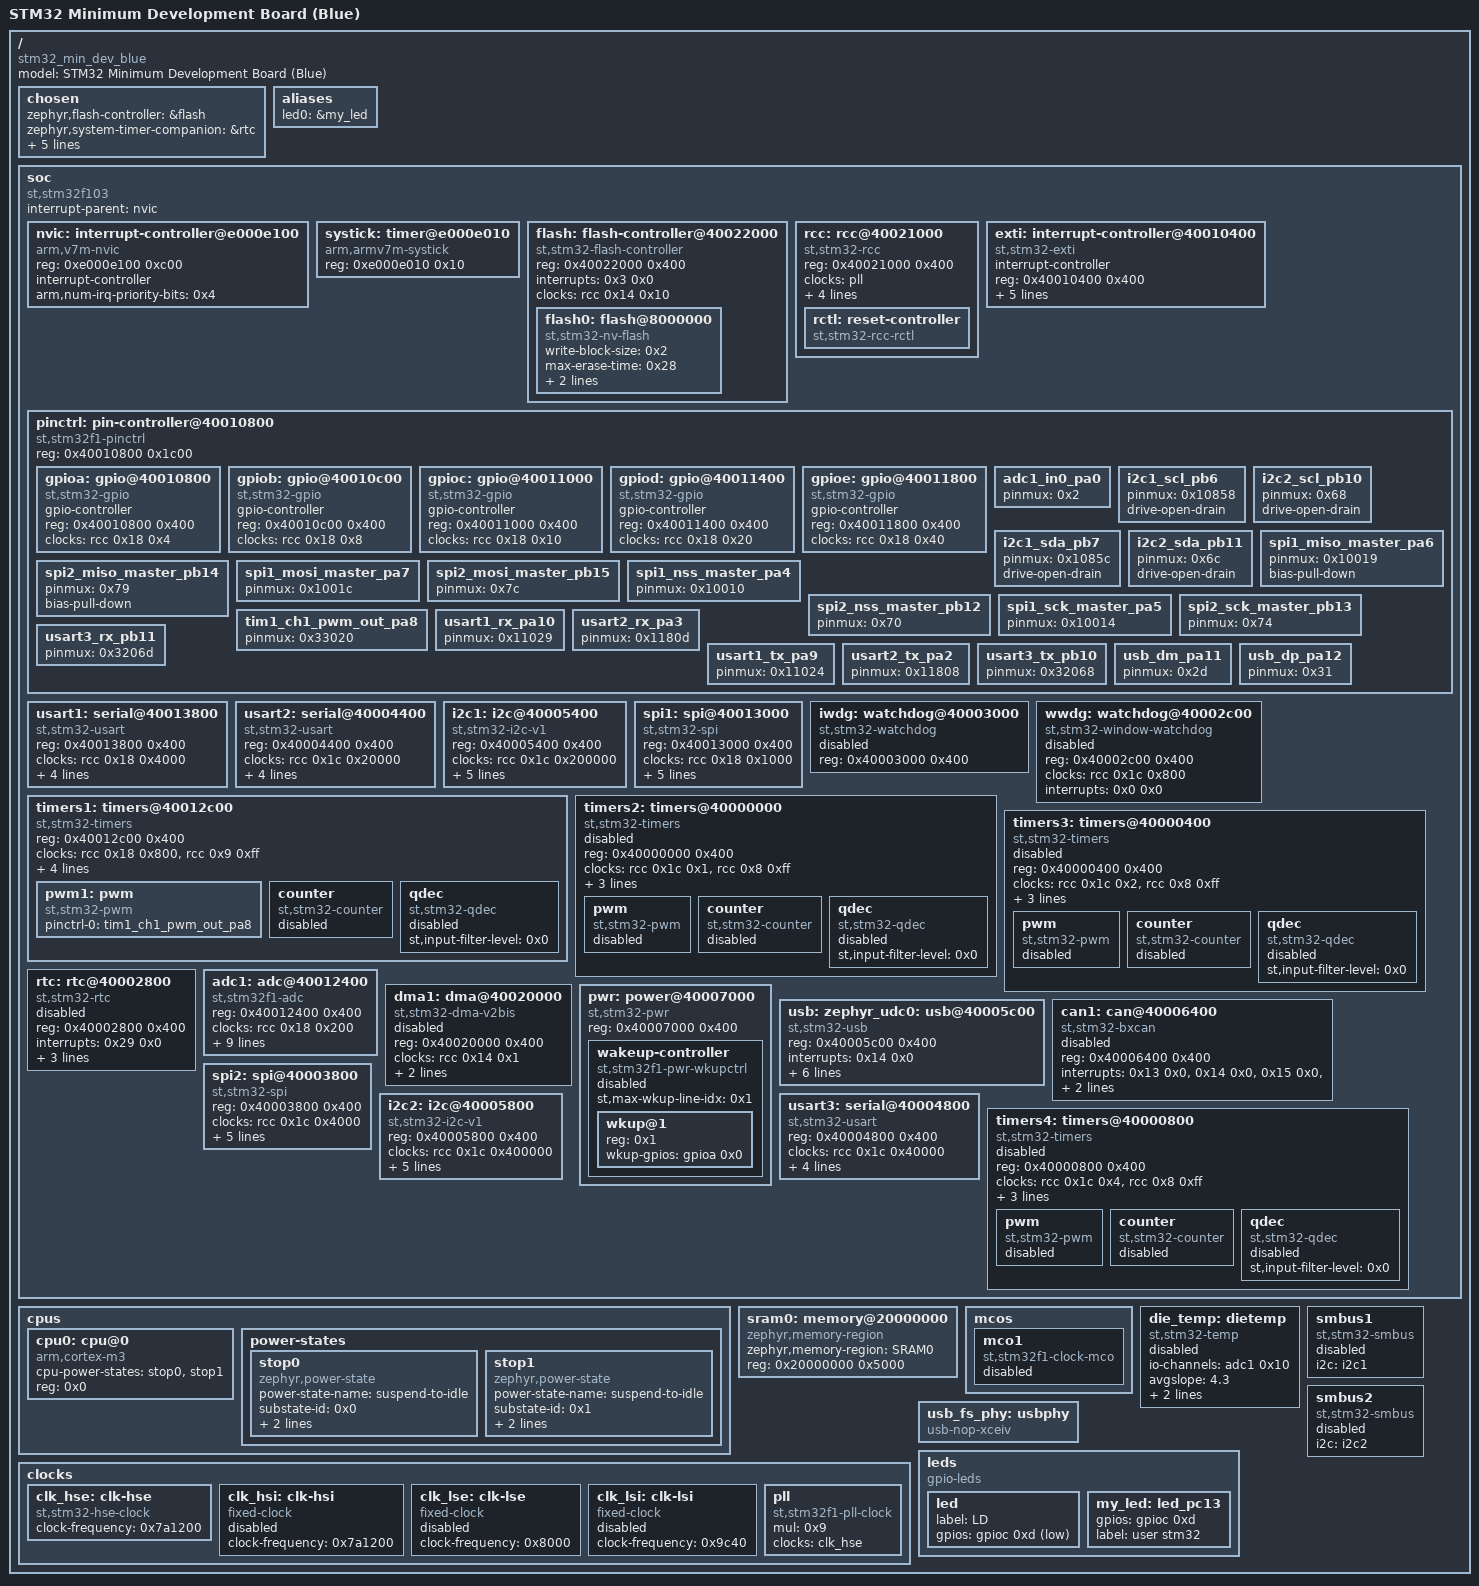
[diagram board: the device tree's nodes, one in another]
/dts-v1/;

/* node '/' defined in zephyr/dts/common/skeleton.dtsi:9 */
/ {
	#address-cells = < 0x1 >;                         /* in zephyr/dts/common/skeleton.dtsi:10 */
	#size-cells = < 0x1 >;                            /* in zephyr/dts/common/skeleton.dtsi:11 */
	model = "STM32 Minimum Development Board (Blue)"; /* in zephyr/boards/others/stm32_min_dev/stm32_min_dev_stm32f103x8_blue.overlay:8 */
	compatible = "stm32_min_dev_blue",
	             "st,stm32f103c8";                    /* in zephyr/boards/others/stm32_min_dev/stm32_min_dev_stm32f103x8_blue.overlay:9 */

	/* node '/chosen' defined in zephyr/dts/common/skeleton.dtsi:13 */
	chosen {
		zephyr,flash-controller = &flash;     /* in zephyr/dts/arm/st/f1/stm32f1.dtsi:24 */
		zephyr,system-timer-companion = &rtc; /* in zephyr/dts/arm/st/f1/stm32f1.dtsi:25 */
		zephyr,console = &usart1;             /* in zephyr/boards/others/stm32_min_dev/stm32_min_dev.dts:16 */
		zephyr,shell-uart = &usart1;          /* in zephyr/boards/others/stm32_min_dev/stm32_min_dev.dts:17 */
		zephyr,osdp-uart = &usart2;           /* in zephyr/boards/others/stm32_min_dev/stm32_min_dev.dts:18 */
		zephyr,sram = &sram0;                 /* in zephyr/boards/others/stm32_min_dev/stm32_min_dev.dts:19 */
		zephyr,flash = &flash0;               /* in zephyr/boards/others/stm32_min_dev/stm32_min_dev.dts:20 */
	};

	/* node '/aliases' defined in zephyr/dts/common/skeleton.dtsi:15 */
	aliases {
		led0 = &my_led; /* in ../Zephyr_Prj/Blink_led/boards/stm32_min_dev_blue.overlay:3 */
	};

	/* node '/soc' defined in zephyr/dts/arm/armv7-m.dtsi:6 */
	soc {
		#address-cells = < 0x1 >;     /* in zephyr/dts/arm/armv7-m.dtsi:7 */
		#size-cells = < 0x1 >;        /* in zephyr/dts/arm/armv7-m.dtsi:8 */
		interrupt-parent = < &nvic >; /* in zephyr/dts/arm/armv7-m.dtsi:10 */
		ranges;                       /* in zephyr/dts/arm/armv7-m.dtsi:11 */
		compatible = "st,stm32f103",
		             "st,stm32f1",
		             "simple-bus";    /* in zephyr/dts/arm/st/f1/stm32f103X6.dtsi:14 */

		/* node '/soc/interrupt-controller@e000e100' defined in zephyr/dts/arm/armv7-m.dtsi:13 */
		nvic: interrupt-controller@e000e100 {
			#address-cells = < 0x1 >;            /* in zephyr/dts/arm/armv7-m.dtsi:14 */
			compatible = "arm,v7m-nvic";         /* in zephyr/dts/arm/armv7-m.dtsi:15 */
			reg = < 0xe000e100 0xc00 >;          /* in zephyr/dts/arm/armv7-m.dtsi:16 */
			interrupt-controller;                /* in zephyr/dts/arm/armv7-m.dtsi:17 */
			#interrupt-cells = < 0x2 >;          /* in zephyr/dts/arm/armv7-m.dtsi:18 */
			arm,num-irq-priority-bits = < 0x4 >; /* in zephyr/dts/arm/st/f1/stm32f1.dtsi:417 */
			phandle = < 0x1 >;                   /* in zephyr/dts/arm/armv7-m.dtsi:10 */
		};

		/* node '/soc/timer@e000e010' defined in zephyr/dts/arm/armv7-m.dtsi:21 */
		systick: timer@e000e010 {
			compatible = "arm,armv7m-systick"; /* in zephyr/dts/arm/armv7-m.dtsi:22 */
			reg = < 0xe000e010 0x10 >;         /* in zephyr/dts/arm/armv7-m.dtsi:23 */
		};

		/* node '/soc/flash-controller@40022000' defined in zephyr/dts/arm/st/f1/stm32f1.dtsi:107 */
		flash: flash-controller@40022000 {
			compatible = "st,stm32-flash-controller",
			             "st,stm32f1-flash-controller"; /* in zephyr/dts/arm/st/f1/stm32f1.dtsi:108 */
			reg = < 0x40022000 0x400 >;                 /* in zephyr/dts/arm/st/f1/stm32f1.dtsi:109 */
			interrupts = < 0x3 0x0 >;                   /* in zephyr/dts/arm/st/f1/stm32f1.dtsi:110 */
			clocks = < &rcc 0x14 0x10 >;                /* in zephyr/dts/arm/st/f1/stm32f1.dtsi:111 */
			#address-cells = < 0x1 >;                   /* in zephyr/dts/arm/st/f1/stm32f1.dtsi:113 */
			#size-cells = < 0x1 >;                      /* in zephyr/dts/arm/st/f1/stm32f1.dtsi:114 */
			ranges;                                     /* in zephyr/dts/arm/st/f1/stm32f1.dtsi:115 */

			/* node '/soc/flash-controller@40022000/flash@8000000' defined in zephyr/dts/arm/st/f1/stm32f1.dtsi:117 */
			flash0: flash@8000000 {
				compatible = "st,stm32-nv-flash",
				             "soc-nv-flash";        /* in zephyr/dts/arm/st/f1/stm32f1.dtsi:118 */
				#address-cells = < 0x1 >;           /* in zephyr/dts/arm/st/f1/stm32f1.dtsi:119 */
				#size-cells = < 0x1 >;              /* in zephyr/dts/arm/st/f1/stm32f1.dtsi:120 */
				write-block-size = < 0x2 >;         /* in zephyr/dts/arm/st/f1/stm32f1.dtsi:121 */
				max-erase-time = < 0x28 >;          /* in zephyr/dts/arm/st/f1/stm32f1.dtsi:123 */
				reg = < 0x8000000 0x10000 >;        /* in zephyr/dts/arm/st/f1/stm32f103X8.dtsi:17 */
				ranges = < 0x0 0x8000000 0x10000 >; /* in zephyr/dts/arm/st/f1/stm32f103X8.dtsi:18 */
				erase-block-size = < 0x400 >;       /* in zephyr/dts/arm/st/f1/stm32f103X8.dtsi:19 */
			};
		};

		/* node '/soc/rcc@40021000' defined in zephyr/dts/arm/st/f1/stm32f1.dtsi:127 */
		rcc: rcc@40021000 {
			compatible = "st,stm32-rcc";     /* in zephyr/dts/arm/st/f1/stm32f1.dtsi:128 */
			#clock-cells = < 0x2 >;          /* in zephyr/dts/arm/st/f1/stm32f1.dtsi:129 */
			reg = < 0x40021000 0x400 >;      /* in zephyr/dts/arm/st/f1/stm32f1.dtsi:130 */
			clocks = < &pll >;               /* in zephyr/boards/others/stm32_min_dev/stm32_min_dev.dts:49 */
			clock-frequency = < 0x44aa200 >; /* in zephyr/boards/others/stm32_min_dev/stm32_min_dev.dts:50 */
			ahb-prescaler = < 0x1 >;         /* in zephyr/boards/others/stm32_min_dev/stm32_min_dev.dts:51 */
			apb1-prescaler = < 0x2 >;        /* in zephyr/boards/others/stm32_min_dev/stm32_min_dev.dts:52 */
			apb2-prescaler = < 0x1 >;        /* in zephyr/boards/others/stm32_min_dev/stm32_min_dev.dts:53 */
			phandle = < 0x2 >;               /* in zephyr/dts/arm/st/f1/stm32f1.dtsi:111 */

			/* node '/soc/rcc@40021000/reset-controller' defined in zephyr/dts/arm/st/f1/stm32f1.dtsi:132 */
			rctl: reset-controller {
				compatible = "st,stm32-rcc-rctl"; /* in zephyr/dts/arm/st/f1/stm32f1.dtsi:133 */
				#reset-cells = < 0x1 >;           /* in zephyr/dts/arm/st/f1/stm32f1.dtsi:134 */
				phandle = < 0x4 >;                /* in zephyr/dts/arm/st/f1/stm32f1.dtsi:205 */
			};
		};

		/* node '/soc/interrupt-controller@40010400' defined in zephyr/dts/arm/st/f1/stm32f1.dtsi:138 */
		exti: interrupt-controller@40010400 {
			compatible = "st,stm32-exti";  /* in zephyr/dts/arm/st/f1/stm32f1.dtsi:139 */
			interrupt-controller;          /* in zephyr/dts/arm/st/f1/stm32f1.dtsi:140 */
			#interrupt-cells = < 0x1 >;    /* in zephyr/dts/arm/st/f1/stm32f1.dtsi:141 */
			#address-cells = < 0x0 >;      /* in zephyr/dts/arm/st/f1/stm32f1.dtsi:142 */
			reg = < 0x40010400 0x400 >;    /* in zephyr/dts/arm/st/f1/stm32f1.dtsi:143 */
			num-lines = < 0x20 >;          /* in zephyr/dts/arm/st/f1/stm32f1.dtsi:144 */
			interrupts = < 0x6 0x0 >,
			             < 0x7 0x0 >,
			             < 0x8 0x0 >,
			             < 0x9 0x0 >,
			             < 0xa 0x0 >,
			             < 0x17 0x0 >,
			             < 0x28 0x0 >;     /* in zephyr/dts/arm/st/f1/stm32f1.dtsi:145 */
			interrupt-names = "line0",
			                  "line1",
			                  "line2",
			                  "line3",
			                  "line4",
			                  "line5-9",
			                  "line10-15"; /* in zephyr/dts/arm/st/f1/stm32f1.dtsi:147 */
			line-ranges = < 0x0 0x1 >,
			              < 0x1 0x1 >,
			              < 0x2 0x1 >,
			              < 0x3 0x1 >,
			              < 0x4 0x1 >,
			              < 0x5 0x5 >,
			              < 0xa 0x6 >;     /* in zephyr/dts/arm/st/f1/stm32f1.dtsi:149 */
		};

		/* node '/soc/pin-controller@40010800' defined in zephyr/dts/arm/st/f1/stm32f1.dtsi:153 */
		pinctrl: pin-controller@40010800 {
			compatible = "st,stm32f1-pinctrl"; /* in zephyr/dts/arm/st/f1/stm32f1.dtsi:154 */
			#address-cells = < 0x1 >;          /* in zephyr/dts/arm/st/f1/stm32f1.dtsi:155 */
			#size-cells = < 0x1 >;             /* in zephyr/dts/arm/st/f1/stm32f1.dtsi:156 */
			reg = < 0x40010800 0x1c00 >;       /* in zephyr/dts/arm/st/f1/stm32f1.dtsi:157 */
			ranges;                            /* in zephyr/dts/arm/st/f1/stm32f1.dtsi:158 */

			/* node '/soc/pin-controller@40010800/gpio@40010800' defined in zephyr/dts/arm/st/f1/stm32f1.dtsi:160 */
			gpioa: gpio@40010800 {
				compatible = "st,stm32-gpio"; /* in zephyr/dts/arm/st/f1/stm32f1.dtsi:161 */
				gpio-controller;              /* in zephyr/dts/arm/st/f1/stm32f1.dtsi:162 */
				#gpio-cells = < 0x2 >;        /* in zephyr/dts/arm/st/f1/stm32f1.dtsi:163 */
				reg = < 0x40010800 0x400 >;   /* in zephyr/dts/arm/st/f1/stm32f1.dtsi:164 */
				clocks = < &rcc 0x18 0x4 >;   /* in zephyr/dts/arm/st/f1/stm32f1.dtsi:165 */
				phandle = < 0x12 >;           /* in zephyr/dts/arm/st/f1/stm32f1.dtsi:392 */
			};

			/* node '/soc/pin-controller@40010800/gpio@40010c00' defined in zephyr/dts/arm/st/f1/stm32f1.dtsi:168 */
			gpiob: gpio@40010c00 {
				compatible = "st,stm32-gpio"; /* in zephyr/dts/arm/st/f1/stm32f1.dtsi:169 */
				gpio-controller;              /* in zephyr/dts/arm/st/f1/stm32f1.dtsi:170 */
				#gpio-cells = < 0x2 >;        /* in zephyr/dts/arm/st/f1/stm32f1.dtsi:171 */
				reg = < 0x40010c00 0x400 >;   /* in zephyr/dts/arm/st/f1/stm32f1.dtsi:172 */
				clocks = < &rcc 0x18 0x8 >;   /* in zephyr/dts/arm/st/f1/stm32f1.dtsi:173 */
				phandle = < 0xb >;            /* in zephyr/boards/others/stm32_min_dev/stm32_min_dev.dts:82 */
			};

			/* node '/soc/pin-controller@40010800/gpio@40011000' defined in zephyr/dts/arm/st/f1/stm32f1.dtsi:176 */
			gpioc: gpio@40011000 {
				compatible = "st,stm32-gpio"; /* in zephyr/dts/arm/st/f1/stm32f1.dtsi:177 */
				gpio-controller;              /* in zephyr/dts/arm/st/f1/stm32f1.dtsi:178 */
				#gpio-cells = < 0x2 >;        /* in zephyr/dts/arm/st/f1/stm32f1.dtsi:179 */
				reg = < 0x40011000 0x400 >;   /* in zephyr/dts/arm/st/f1/stm32f1.dtsi:180 */
				clocks = < &rcc 0x18 0x10 >;  /* in zephyr/dts/arm/st/f1/stm32f1.dtsi:181 */
				status = "okay";              /* in ../Zephyr_Prj/Blink_led/boards/stm32_min_dev_blue.overlay:17 */
				phandle = < 0x24 >;           /* in zephyr/boards/others/stm32_min_dev/stm32_min_dev_stm32f103x8_blue.overlay:13 */
			};

			/* node '/soc/pin-controller@40010800/gpio@40011400' defined in zephyr/dts/arm/st/f1/stm32f1.dtsi:184 */
			gpiod: gpio@40011400 {
				compatible = "st,stm32-gpio"; /* in zephyr/dts/arm/st/f1/stm32f1.dtsi:185 */
				gpio-controller;              /* in zephyr/dts/arm/st/f1/stm32f1.dtsi:186 */
				#gpio-cells = < 0x2 >;        /* in zephyr/dts/arm/st/f1/stm32f1.dtsi:187 */
				reg = < 0x40011400 0x400 >;   /* in zephyr/dts/arm/st/f1/stm32f1.dtsi:188 */
				clocks = < &rcc 0x18 0x20 >;  /* in zephyr/dts/arm/st/f1/stm32f1.dtsi:189 */
			};

			/* node '/soc/pin-controller@40010800/gpio@40011800' defined in zephyr/dts/arm/st/f1/stm32f1.dtsi:192 */
			gpioe: gpio@40011800 {
				compatible = "st,stm32-gpio"; /* in zephyr/dts/arm/st/f1/stm32f1.dtsi:193 */
				gpio-controller;              /* in zephyr/dts/arm/st/f1/stm32f1.dtsi:194 */
				#gpio-cells = < 0x2 >;        /* in zephyr/dts/arm/st/f1/stm32f1.dtsi:195 */
				reg = < 0x40011800 0x400 >;   /* in zephyr/dts/arm/st/f1/stm32f1.dtsi:196 */
				clocks = < &rcc 0x18 0x40 >;  /* in zephyr/dts/arm/st/f1/stm32f1.dtsi:197 */
			};

			/* node '/soc/pin-controller@40010800/adc1_in0_pa0' defined in modules/hal/stm32/dts/st/f1/stm32f103r(8-b)tx-pinctrl.dtsi:11 */
			adc1_in0_pa0: adc1_in0_pa0 {
				pinmux = < 0x2 >;   /* in modules/hal/stm32/dts/st/f1/stm32f103r(8-b)tx-pinctrl.dtsi:12 */
				phandle = < 0x11 >; /* in zephyr/boards/others/stm32_min_dev/stm32_min_dev.dts:127 */
			};

			/* node '/soc/pin-controller@40010800/i2c1_scl_pb6' defined in modules/hal/stm32/dts/st/f1/stm32f103r(8-b)tx-pinctrl.dtsi:363 */
			i2c1_scl_pb6: i2c1_scl_pb6 {
				pinmux = < 0x10858 >; /* in modules/hal/stm32/dts/st/f1/stm32f103r(8-b)tx-pinctrl.dtsi:364 */
				drive-open-drain;     /* in modules/hal/stm32/dts/st/f1/stm32f103r(8-b)tx-pinctrl.dtsi:365 */
				phandle = < 0x9 >;    /* in zephyr/boards/others/stm32_min_dev/stm32_min_dev.dts:79 */
			};

			/* node '/soc/pin-controller@40010800/i2c2_scl_pb10' defined in modules/hal/stm32/dts/st/f1/stm32f103r(8-b)tx-pinctrl.dtsi:373 */
			i2c2_scl_pb10: i2c2_scl_pb10 {
				pinmux = < 0x68 >;  /* in modules/hal/stm32/dts/st/f1/stm32f103r(8-b)tx-pinctrl.dtsi:374 */
				drive-open-drain;   /* in modules/hal/stm32/dts/st/f1/stm32f103r(8-b)tx-pinctrl.dtsi:375 */
				phandle = < 0x1c >; /* in zephyr/boards/others/stm32_min_dev/stm32_min_dev.dts:88 */
			};

			/* node '/soc/pin-controller@40010800/i2c1_sda_pb7' defined in modules/hal/stm32/dts/st/f1/stm32f103r(8-b)tx-pinctrl.dtsi:379 */
			i2c1_sda_pb7: i2c1_sda_pb7 {
				pinmux = < 0x1085c >; /* in modules/hal/stm32/dts/st/f1/stm32f103r(8-b)tx-pinctrl.dtsi:380 */
				drive-open-drain;     /* in modules/hal/stm32/dts/st/f1/stm32f103r(8-b)tx-pinctrl.dtsi:381 */
				phandle = < 0xa >;    /* in zephyr/boards/others/stm32_min_dev/stm32_min_dev.dts:79 */
			};

			/* node '/soc/pin-controller@40010800/i2c2_sda_pb11' defined in modules/hal/stm32/dts/st/f1/stm32f103r(8-b)tx-pinctrl.dtsi:389 */
			i2c2_sda_pb11: i2c2_sda_pb11 {
				pinmux = < 0x6c >;  /* in modules/hal/stm32/dts/st/f1/stm32f103r(8-b)tx-pinctrl.dtsi:390 */
				drive-open-drain;   /* in modules/hal/stm32/dts/st/f1/stm32f103r(8-b)tx-pinctrl.dtsi:391 */
				phandle = < 0x1d >; /* in zephyr/boards/others/stm32_min_dev/stm32_min_dev.dts:88 */
			};

			/* node '/soc/pin-controller@40010800/spi1_miso_master_pa6' defined in modules/hal/stm32/dts/st/f1/stm32f103r(8-b)tx-pinctrl.dtsi:426 */
			spi1_miso_master_pa6: spi1_miso_master_pa6 {
				pinmux = < 0x10019 >; /* in modules/hal/stm32/dts/st/f1/stm32f103r(8-b)tx-pinctrl.dtsi:427 */
				bias-pull-down;       /* in modules/hal/stm32/dts/st/f1/stm32f103r(8-b)tx-pinctrl.dtsi:428 */
				phandle = < 0xe >;    /* in zephyr/boards/others/stm32_min_dev/stm32_min_dev.dts:97 */
			};

			/* node '/soc/pin-controller@40010800/spi2_miso_master_pb14' defined in modules/hal/stm32/dts/st/f1/stm32f103r(8-b)tx-pinctrl.dtsi:436 */
			spi2_miso_master_pb14: spi2_miso_master_pb14 {
				pinmux = < 0x79 >;  /* in modules/hal/stm32/dts/st/f1/stm32f103r(8-b)tx-pinctrl.dtsi:437 */
				bias-pull-down;     /* in modules/hal/stm32/dts/st/f1/stm32f103r(8-b)tx-pinctrl.dtsi:438 */
				phandle = < 0x18 >; /* in zephyr/boards/others/stm32_min_dev/stm32_min_dev.dts:104 */
			};

			/* node '/soc/pin-controller@40010800/spi1_mosi_master_pa7' defined in modules/hal/stm32/dts/st/f1/stm32f103r(8-b)tx-pinctrl.dtsi:442 */
			spi1_mosi_master_pa7: spi1_mosi_master_pa7 {
				pinmux = < 0x1001c >; /* in modules/hal/stm32/dts/st/f1/stm32f103r(8-b)tx-pinctrl.dtsi:443 */
				phandle = < 0xf >;    /* in zephyr/boards/others/stm32_min_dev/stm32_min_dev.dts:97 */
			};

			/* node '/soc/pin-controller@40010800/spi2_mosi_master_pb15' defined in modules/hal/stm32/dts/st/f1/stm32f103r(8-b)tx-pinctrl.dtsi:450 */
			spi2_mosi_master_pb15: spi2_mosi_master_pb15 {
				pinmux = < 0x7c >;  /* in modules/hal/stm32/dts/st/f1/stm32f103r(8-b)tx-pinctrl.dtsi:451 */
				phandle = < 0x19 >; /* in zephyr/boards/others/stm32_min_dev/stm32_min_dev.dts:104 */
			};

			/* node '/soc/pin-controller@40010800/spi1_nss_master_pa4' defined in modules/hal/stm32/dts/st/f1/stm32f103r(8-b)tx-pinctrl.dtsi:455 */
			spi1_nss_master_pa4: spi1_nss_master_pa4 {
				pinmux = < 0x10010 >; /* in modules/hal/stm32/dts/st/f1/stm32f103r(8-b)tx-pinctrl.dtsi:456 */
				phandle = < 0xc >;    /* in zephyr/boards/others/stm32_min_dev/stm32_min_dev.dts:97 */
			};

			/* node '/soc/pin-controller@40010800/spi2_nss_master_pb12' defined in modules/hal/stm32/dts/st/f1/stm32f103r(8-b)tx-pinctrl.dtsi:463 */
			spi2_nss_master_pb12: spi2_nss_master_pb12 {
				pinmux = < 0x70 >;  /* in modules/hal/stm32/dts/st/f1/stm32f103r(8-b)tx-pinctrl.dtsi:464 */
				phandle = < 0x16 >; /* in zephyr/boards/others/stm32_min_dev/stm32_min_dev.dts:104 */
			};

			/* node '/soc/pin-controller@40010800/spi1_sck_master_pa5' defined in modules/hal/stm32/dts/st/f1/stm32f103r(8-b)tx-pinctrl.dtsi:468 */
			spi1_sck_master_pa5: spi1_sck_master_pa5 {
				pinmux = < 0x10014 >; /* in modules/hal/stm32/dts/st/f1/stm32f103r(8-b)tx-pinctrl.dtsi:469 */
				phandle = < 0xd >;    /* in zephyr/boards/others/stm32_min_dev/stm32_min_dev.dts:97 */
			};

			/* node '/soc/pin-controller@40010800/spi2_sck_master_pb13' defined in modules/hal/stm32/dts/st/f1/stm32f103r(8-b)tx-pinctrl.dtsi:476 */
			spi2_sck_master_pb13: spi2_sck_master_pb13 {
				pinmux = < 0x74 >;  /* in modules/hal/stm32/dts/st/f1/stm32f103r(8-b)tx-pinctrl.dtsi:477 */
				phandle = < 0x17 >; /* in zephyr/boards/others/stm32_min_dev/stm32_min_dev.dts:104 */
			};

			/* node '/soc/pin-controller@40010800/tim1_ch1_pwm_out_pa8' defined in modules/hal/stm32/dts/st/f1/stm32f103r(8-b)tx-pinctrl.dtsi:734 */
			tim1_ch1_pwm_out_pa8: tim1_ch1_pwm_out_pa8 {
				pinmux = < 0x33020 >; /* in modules/hal/stm32/dts/st/f1/stm32f103r(8-b)tx-pinctrl.dtsi:735 */
				phandle = < 0x10 >;   /* in zephyr/boards/others/stm32_min_dev/stm32_min_dev.dts:115 */
			};

			/* node '/soc/pin-controller@40010800/usart1_rx_pa10' defined in modules/hal/stm32/dts/st/f1/stm32f103r(8-b)tx-pinctrl.dtsi:957 */
			usart1_rx_pa10: usart1_rx_pa10 {
				pinmux = < 0x11029 >; /* in modules/hal/stm32/dts/st/f1/stm32f103r(8-b)tx-pinctrl.dtsi:958 */
				phandle = < 0x6 >;    /* in zephyr/boards/others/stm32_min_dev/stm32_min_dev.dts:58 */
			};

			/* node '/soc/pin-controller@40010800/usart2_rx_pa3' defined in modules/hal/stm32/dts/st/f1/stm32f103r(8-b)tx-pinctrl.dtsi:965 */
			usart2_rx_pa3: usart2_rx_pa3 {
				pinmux = < 0x1180d >; /* in modules/hal/stm32/dts/st/f1/stm32f103r(8-b)tx-pinctrl.dtsi:966 */
				phandle = < 0x8 >;    /* in zephyr/boards/others/stm32_min_dev/stm32_min_dev.dts:65 */
			};

			/* node '/soc/pin-controller@40010800/usart3_rx_pb11' defined in modules/hal/stm32/dts/st/f1/stm32f103r(8-b)tx-pinctrl.dtsi:969 */
			usart3_rx_pb11: usart3_rx_pb11 {
				pinmux = < 0x3206d >; /* in modules/hal/stm32/dts/st/f1/stm32f103r(8-b)tx-pinctrl.dtsi:970 */
				phandle = < 0x1b >;   /* in zephyr/boards/others/stm32_min_dev/stm32_min_dev.dts:72 */
			};

			/* node '/soc/pin-controller@40010800/usart1_tx_pa9' defined in modules/hal/stm32/dts/st/f1/stm32f103r(8-b)tx-pinctrl.dtsi:978 */
			usart1_tx_pa9: usart1_tx_pa9 {
				pinmux = < 0x11024 >; /* in modules/hal/stm32/dts/st/f1/stm32f103r(8-b)tx-pinctrl.dtsi:979 */
				phandle = < 0x5 >;    /* in zephyr/boards/others/stm32_min_dev/stm32_min_dev.dts:58 */
			};

			/* node '/soc/pin-controller@40010800/usart2_tx_pa2' defined in modules/hal/stm32/dts/st/f1/stm32f103r(8-b)tx-pinctrl.dtsi:986 */
			usart2_tx_pa2: usart2_tx_pa2 {
				pinmux = < 0x11808 >; /* in modules/hal/stm32/dts/st/f1/stm32f103r(8-b)tx-pinctrl.dtsi:987 */
				phandle = < 0x7 >;    /* in zephyr/boards/others/stm32_min_dev/stm32_min_dev.dts:65 */
			};

			/* node '/soc/pin-controller@40010800/usart3_tx_pb10' defined in modules/hal/stm32/dts/st/f1/stm32f103r(8-b)tx-pinctrl.dtsi:990 */
			usart3_tx_pb10: usart3_tx_pb10 {
				pinmux = < 0x32068 >; /* in modules/hal/stm32/dts/st/f1/stm32f103r(8-b)tx-pinctrl.dtsi:991 */
				phandle = < 0x1a >;   /* in zephyr/boards/others/stm32_min_dev/stm32_min_dev.dts:72 */
			};

			/* node '/soc/pin-controller@40010800/usb_dm_pa11' defined in modules/hal/stm32/dts/st/f1/stm32f103r(8-b)tx-pinctrl.dtsi:999 */
			usb_dm_pa11: usb_dm_pa11 {
				pinmux = < 0x2d >;  /* in modules/hal/stm32/dts/st/f1/stm32f103r(8-b)tx-pinctrl.dtsi:1000 */
				phandle = < 0x14 >; /* in zephyr/boards/others/stm32_min_dev/stm32_min_dev.dts:121 */
			};

			/* node '/soc/pin-controller@40010800/usb_dp_pa12' defined in modules/hal/stm32/dts/st/f1/stm32f103r(8-b)tx-pinctrl.dtsi:1003 */
			usb_dp_pa12: usb_dp_pa12 {
				pinmux = < 0x31 >;  /* in modules/hal/stm32/dts/st/f1/stm32f103r(8-b)tx-pinctrl.dtsi:1004 */
				phandle = < 0x15 >; /* in zephyr/boards/others/stm32_min_dev/stm32_min_dev.dts:121 */
			};
		};

		/* node '/soc/serial@40013800' defined in zephyr/dts/arm/st/f1/stm32f1.dtsi:201 */
		usart1: serial@40013800 {
			compatible = "st,stm32-usart",
			             "st,stm32-uart";                   /* in zephyr/dts/arm/st/f1/stm32f1.dtsi:202 */
			reg = < 0x40013800 0x400 >;                     /* in zephyr/dts/arm/st/f1/stm32f1.dtsi:203 */
			clocks = < &rcc 0x18 0x4000 >;                  /* in zephyr/dts/arm/st/f1/stm32f1.dtsi:204 */
			resets = < &rctl 0x18e >;                       /* in zephyr/dts/arm/st/f1/stm32f1.dtsi:205 */
			interrupts = < 0x25 0x0 >;                      /* in zephyr/dts/arm/st/f1/stm32f1.dtsi:206 */
			pinctrl-0 = < &usart1_tx_pa9 &usart1_rx_pa10 >; /* in zephyr/boards/others/stm32_min_dev/stm32_min_dev.dts:58 */
			current-speed = < 0x1c200 >;                    /* in zephyr/boards/others/stm32_min_dev/stm32_min_dev.dts:59 */
			pinctrl-names = "default";                      /* in zephyr/boards/others/stm32_min_dev/stm32_min_dev.dts:60 */
			status = "okay";                                /* in zephyr/boards/others/stm32_min_dev/stm32_min_dev.dts:61 */
		};

		/* node '/soc/serial@40004400' defined in zephyr/dts/arm/st/f1/stm32f1.dtsi:210 */
		usart2: serial@40004400 {
			compatible = "st,stm32-usart",
			             "st,stm32-uart";                  /* in zephyr/dts/arm/st/f1/stm32f1.dtsi:211 */
			reg = < 0x40004400 0x400 >;                    /* in zephyr/dts/arm/st/f1/stm32f1.dtsi:212 */
			clocks = < &rcc 0x1c 0x20000 >;                /* in zephyr/dts/arm/st/f1/stm32f1.dtsi:213 */
			resets = < &rctl 0x211 >;                      /* in zephyr/dts/arm/st/f1/stm32f1.dtsi:214 */
			interrupts = < 0x26 0x0 >;                     /* in zephyr/dts/arm/st/f1/stm32f1.dtsi:215 */
			pinctrl-0 = < &usart2_tx_pa2 &usart2_rx_pa3 >; /* in zephyr/boards/others/stm32_min_dev/stm32_min_dev.dts:65 */
			current-speed = < 0x1c200 >;                   /* in zephyr/boards/others/stm32_min_dev/stm32_min_dev.dts:66 */
			pinctrl-names = "default";                     /* in zephyr/boards/others/stm32_min_dev/stm32_min_dev.dts:67 */
			status = "okay";                               /* in zephyr/boards/others/stm32_min_dev/stm32_min_dev.dts:68 */
		};

		/* node '/soc/i2c@40005400' defined in zephyr/dts/arm/st/f1/stm32f1.dtsi:219 */
		i2c1: i2c@40005400 {
			compatible = "st,stm32-i2c-v1";              /* in zephyr/dts/arm/st/f1/stm32f1.dtsi:220 */
			#address-cells = < 0x1 >;                    /* in zephyr/dts/arm/st/f1/stm32f1.dtsi:222 */
			#size-cells = < 0x0 >;                       /* in zephyr/dts/arm/st/f1/stm32f1.dtsi:223 */
			reg = < 0x40005400 0x400 >;                  /* in zephyr/dts/arm/st/f1/stm32f1.dtsi:224 */
			clocks = < &rcc 0x1c 0x200000 >;             /* in zephyr/dts/arm/st/f1/stm32f1.dtsi:225 */
			interrupts = < 0x1f 0x0 >,
			             < 0x20 0x0 >;                   /* in zephyr/dts/arm/st/f1/stm32f1.dtsi:226 */
			interrupt-names = "event",
			                  "error";                   /* in zephyr/dts/arm/st/f1/stm32f1.dtsi:227 */
			pinctrl-0 = < &i2c1_scl_pb6 &i2c1_sda_pb7 >; /* in zephyr/boards/others/stm32_min_dev/stm32_min_dev.dts:79 */
			status = "okay";                             /* in zephyr/boards/others/stm32_min_dev/stm32_min_dev.dts:80 */
			pinctrl-names = "default";                   /* in zephyr/boards/others/stm32_min_dev/stm32_min_dev.dts:81 */
			scl-gpios = < &gpiob 0x6 0x0 >;              /* in zephyr/boards/others/stm32_min_dev/stm32_min_dev.dts:82 */
			sda-gpios = < &gpiob 0x7 0x0 >;              /* in zephyr/boards/others/stm32_min_dev/stm32_min_dev.dts:83 */
			clock-frequency = < 0x61a80 >;               /* in zephyr/boards/others/stm32_min_dev/stm32_min_dev.dts:84 */
			phandle = < 0x22 >;                          /* in zephyr/dts/arm/st/f1/stm32f1.dtsi:411 */
		};

		/* node '/soc/spi@40013000' defined in zephyr/dts/arm/st/f1/stm32f1.dtsi:231 */
		spi1: spi@40013000 {
			compatible = "st,stm32-spi";                                                                           /* in zephyr/dts/arm/st/f1/stm32f1.dtsi:232 */
			#address-cells = < 0x1 >;                                                                              /* in zephyr/dts/arm/st/f1/stm32f1.dtsi:233 */
			#size-cells = < 0x0 >;                                                                                 /* in zephyr/dts/arm/st/f1/stm32f1.dtsi:234 */
			reg = < 0x40013000 0x400 >;                                                                            /* in zephyr/dts/arm/st/f1/stm32f1.dtsi:235 */
			clocks = < &rcc 0x18 0x1000 >;                                                                         /* in zephyr/dts/arm/st/f1/stm32f1.dtsi:236 */
			interrupts = < 0x23 0x0 >;                                                                             /* in zephyr/dts/arm/st/f1/stm32f1.dtsi:237 */
			st,spi-data-width = "limited-8-16-bit";                                                                /* in zephyr/dts/arm/st/f1/stm32f1.dtsi:238 */
			pinctrl-0 = < &spi1_nss_master_pa4 &spi1_sck_master_pa5 &spi1_miso_master_pa6 &spi1_mosi_master_pa7 >; /* in zephyr/boards/others/stm32_min_dev/stm32_min_dev.dts:97 */
			pinctrl-names = "default";                                                                             /* in zephyr/boards/others/stm32_min_dev/stm32_min_dev.dts:99 */
			status = "okay";                                                                                       /* in zephyr/boards/others/stm32_min_dev/stm32_min_dev.dts:100 */
		};

		/* node '/soc/watchdog@40003000' defined in zephyr/dts/arm/st/f1/stm32f1.dtsi:242 */
		iwdg: watchdog@40003000 {
			compatible = "st,stm32-watchdog"; /* in zephyr/dts/arm/st/f1/stm32f1.dtsi:243 */
			reg = < 0x40003000 0x400 >;       /* in zephyr/dts/arm/st/f1/stm32f1.dtsi:244 */
			status = "disabled";              /* in zephyr/dts/arm/st/f1/stm32f1.dtsi:245 */
		};

		/* node '/soc/watchdog@40002c00' defined in zephyr/dts/arm/st/f1/stm32f1.dtsi:248 */
		wwdg: watchdog@40002c00 {
			compatible = "st,stm32-window-watchdog"; /* in zephyr/dts/arm/st/f1/stm32f1.dtsi:249 */
			reg = < 0x40002c00 0x400 >;              /* in zephyr/dts/arm/st/f1/stm32f1.dtsi:250 */
			clocks = < &rcc 0x1c 0x800 >;            /* in zephyr/dts/arm/st/f1/stm32f1.dtsi:251 */
			interrupts = < 0x0 0x0 >;                /* in zephyr/dts/arm/st/f1/stm32f1.dtsi:252 */
			status = "disabled";                     /* in zephyr/dts/arm/st/f1/stm32f1.dtsi:253 */
		};

		/* node '/soc/timers@40012c00' defined in zephyr/dts/arm/st/f1/stm32f1.dtsi:256 */
		timers1: timers@40012c00 {
			compatible = "st,stm32-timers"; /* in zephyr/dts/arm/st/f1/stm32f1.dtsi:257 */
			reg = < 0x40012c00 0x400 >;     /* in zephyr/dts/arm/st/f1/stm32f1.dtsi:258 */
			clocks = < &rcc 0x18 0x800 >,
			         < &rcc 0x9 0xff >;     /* in zephyr/dts/arm/st/f1/stm32f1.dtsi:259 */
			resets = < &rctl 0x18b >;       /* in zephyr/dts/arm/st/f1/stm32f1.dtsi:261 */
			interrupts = < 0x18 0x0 >,
			             < 0x19 0x0 >,
			             < 0x1a 0x0 >,
			             < 0x1b 0x0 >;      /* in zephyr/dts/arm/st/f1/stm32f1.dtsi:262 */
			interrupt-names = "brk",
			                  "up",
			                  "trgcom",
			                  "cc";         /* in zephyr/dts/arm/st/f1/stm32f1.dtsi:263 */
			st,prescaler = < 0x0 >;         /* in zephyr/dts/arm/st/f1/stm32f1.dtsi:264 */
			status = "okay";                /* in zephyr/boards/others/stm32_min_dev/stm32_min_dev.dts:111 */

			/* node '/soc/timers@40012c00/pwm' defined in zephyr/dts/arm/st/f1/stm32f1.dtsi:267 */
			pwm1: pwm {
				compatible = "st,stm32-pwm";           /* in zephyr/dts/arm/st/f1/stm32f1.dtsi:268 */
				#pwm-cells = < 0x3 >;                  /* in zephyr/dts/arm/st/f1/stm32f1.dtsi:270 */
				status = "okay";                       /* in zephyr/boards/others/stm32_min_dev/stm32_min_dev.dts:114 */
				pinctrl-0 = < &tim1_ch1_pwm_out_pa8 >; /* in zephyr/boards/others/stm32_min_dev/stm32_min_dev.dts:115 */
				pinctrl-names = "default";             /* in zephyr/boards/others/stm32_min_dev/stm32_min_dev.dts:116 */
			};

			/* node '/soc/timers@40012c00/counter' defined in zephyr/dts/arm/st/f1/stm32f1.dtsi:273 */
			counter {
				compatible = "st,stm32-counter"; /* in zephyr/dts/arm/st/f1/stm32f1.dtsi:274 */
				status = "disabled";             /* in zephyr/dts/arm/st/f1/stm32f1.dtsi:275 */
			};

			/* node '/soc/timers@40012c00/qdec' defined in zephyr/dts/arm/st/f1/stm32f1.dtsi:278 */
			qdec {
				compatible = "st,stm32-qdec";    /* in zephyr/dts/arm/st/f1/stm32f1.dtsi:279 */
				st,input-filter-level = < 0x0 >; /* in zephyr/dts/arm/st/f1/stm32f1.dtsi:280 */
				status = "disabled";             /* in zephyr/dts/arm/st/f1/stm32f1.dtsi:281 */
			};
		};

		/* node '/soc/timers@40000000' defined in zephyr/dts/arm/st/f1/stm32f1.dtsi:285 */
		timers2: timers@40000000 {
			compatible = "st,stm32-timers"; /* in zephyr/dts/arm/st/f1/stm32f1.dtsi:286 */
			reg = < 0x40000000 0x400 >;     /* in zephyr/dts/arm/st/f1/stm32f1.dtsi:287 */
			clocks = < &rcc 0x1c 0x1 >,
			         < &rcc 0x8 0xff >;     /* in zephyr/dts/arm/st/f1/stm32f1.dtsi:288 */
			resets = < &rctl 0x200 >;       /* in zephyr/dts/arm/st/f1/stm32f1.dtsi:290 */
			interrupts = < 0x1c 0x0 >;      /* in zephyr/dts/arm/st/f1/stm32f1.dtsi:291 */
			interrupt-names = "global";     /* in zephyr/dts/arm/st/f1/stm32f1.dtsi:292 */
			st,prescaler = < 0x0 >;         /* in zephyr/dts/arm/st/f1/stm32f1.dtsi:293 */
			status = "disabled";            /* in zephyr/dts/arm/st/f1/stm32f1.dtsi:294 */

			/* node '/soc/timers@40000000/pwm' defined in zephyr/dts/arm/st/f1/stm32f1.dtsi:296 */
			pwm {
				compatible = "st,stm32-pwm"; /* in zephyr/dts/arm/st/f1/stm32f1.dtsi:297 */
				status = "disabled";         /* in zephyr/dts/arm/st/f1/stm32f1.dtsi:298 */
				#pwm-cells = < 0x3 >;        /* in zephyr/dts/arm/st/f1/stm32f1.dtsi:299 */
			};

			/* node '/soc/timers@40000000/counter' defined in zephyr/dts/arm/st/f1/stm32f1.dtsi:302 */
			counter {
				compatible = "st,stm32-counter"; /* in zephyr/dts/arm/st/f1/stm32f1.dtsi:303 */
				status = "disabled";             /* in zephyr/dts/arm/st/f1/stm32f1.dtsi:304 */
			};

			/* node '/soc/timers@40000000/qdec' defined in zephyr/dts/arm/st/f1/stm32f1.dtsi:307 */
			qdec {
				compatible = "st,stm32-qdec";    /* in zephyr/dts/arm/st/f1/stm32f1.dtsi:308 */
				st,input-filter-level = < 0x0 >; /* in zephyr/dts/arm/st/f1/stm32f1.dtsi:309 */
				status = "disabled";             /* in zephyr/dts/arm/st/f1/stm32f1.dtsi:310 */
			};
		};

		/* node '/soc/timers@40000400' defined in zephyr/dts/arm/st/f1/stm32f1.dtsi:314 */
		timers3: timers@40000400 {
			compatible = "st,stm32-timers"; /* in zephyr/dts/arm/st/f1/stm32f1.dtsi:315 */
			reg = < 0x40000400 0x400 >;     /* in zephyr/dts/arm/st/f1/stm32f1.dtsi:316 */
			clocks = < &rcc 0x1c 0x2 >,
			         < &rcc 0x8 0xff >;     /* in zephyr/dts/arm/st/f1/stm32f1.dtsi:317 */
			resets = < &rctl 0x201 >;       /* in zephyr/dts/arm/st/f1/stm32f1.dtsi:319 */
			interrupts = < 0x1d 0x0 >;      /* in zephyr/dts/arm/st/f1/stm32f1.dtsi:320 */
			interrupt-names = "global";     /* in zephyr/dts/arm/st/f1/stm32f1.dtsi:321 */
			st,prescaler = < 0x0 >;         /* in zephyr/dts/arm/st/f1/stm32f1.dtsi:322 */
			status = "disabled";            /* in zephyr/dts/arm/st/f1/stm32f1.dtsi:323 */

			/* node '/soc/timers@40000400/pwm' defined in zephyr/dts/arm/st/f1/stm32f1.dtsi:325 */
			pwm {
				compatible = "st,stm32-pwm"; /* in zephyr/dts/arm/st/f1/stm32f1.dtsi:326 */
				status = "disabled";         /* in zephyr/dts/arm/st/f1/stm32f1.dtsi:327 */
				#pwm-cells = < 0x3 >;        /* in zephyr/dts/arm/st/f1/stm32f1.dtsi:328 */
			};

			/* node '/soc/timers@40000400/counter' defined in zephyr/dts/arm/st/f1/stm32f1.dtsi:331 */
			counter {
				compatible = "st,stm32-counter"; /* in zephyr/dts/arm/st/f1/stm32f1.dtsi:332 */
				status = "disabled";             /* in zephyr/dts/arm/st/f1/stm32f1.dtsi:333 */
			};

			/* node '/soc/timers@40000400/qdec' defined in zephyr/dts/arm/st/f1/stm32f1.dtsi:336 */
			qdec {
				compatible = "st,stm32-qdec";    /* in zephyr/dts/arm/st/f1/stm32f1.dtsi:337 */
				st,input-filter-level = < 0x0 >; /* in zephyr/dts/arm/st/f1/stm32f1.dtsi:338 */
				status = "disabled";             /* in zephyr/dts/arm/st/f1/stm32f1.dtsi:339 */
			};
		};

		/* node '/soc/rtc@40002800' defined in zephyr/dts/arm/st/f1/stm32f1.dtsi:343 */
		rtc: rtc@40002800 {
			compatible = "st,stm32-rtc";       /* in zephyr/dts/arm/st/f1/stm32f1.dtsi:344 */
			reg = < 0x40002800 0x400 >;        /* in zephyr/dts/arm/st/f1/stm32f1.dtsi:345 */
			interrupts = < 0x29 0x0 >;         /* in zephyr/dts/arm/st/f1/stm32f1.dtsi:346 */
			clocks = < &rcc 0x1c 0x10000000 >; /* in zephyr/dts/arm/st/f1/stm32f1.dtsi:347 */
			prescaler = < 0x8000 >;            /* in zephyr/dts/arm/st/f1/stm32f1.dtsi:348 */
			alrm-exti-line = < 0x11 >;         /* in zephyr/dts/arm/st/f1/stm32f1.dtsi:349 */
			status = "disabled";               /* in zephyr/dts/arm/st/f1/stm32f1.dtsi:350 */
		};

		/* node '/soc/adc@40012400' defined in zephyr/dts/arm/st/f1/stm32f1.dtsi:353 */
		adc1: adc@40012400 {
			compatible = "st,stm32f1-adc",
			             "st,stm32-adc";                               /* in zephyr/dts/arm/st/f1/stm32f1.dtsi:354 */
			reg = < 0x40012400 0x400 >;                                /* in zephyr/dts/arm/st/f1/stm32f1.dtsi:355 */
			clocks = < &rcc 0x18 0x200 >;                              /* in zephyr/dts/arm/st/f1/stm32f1.dtsi:356 */
			clock-names = "adcx";                                      /* in zephyr/dts/arm/st/f1/stm32f1.dtsi:357 */
			interrupts = < 0x12 0x0 >;                                 /* in zephyr/dts/arm/st/f1/stm32f1.dtsi:358 */
			#io-channel-cells = < 0x1 >;                               /* in zephyr/dts/arm/st/f1/stm32f1.dtsi:359 */
			st,adc-resolutions = < 0xc >;                              /* in zephyr/dts/arm/st/f1/stm32f1.dtsi:360 */
			sampling-times = < 0x2 0x8 0xe 0x1d 0x2a 0x38 0x48 0xf0 >; /* in zephyr/dts/arm/st/f1/stm32f1.dtsi:361 */
			st,adc-sequencer = "programmable";                         /* in zephyr/dts/arm/st/f1/stm32f1.dtsi:362 */
			st,adc-oversampler = "none";                               /* in zephyr/dts/arm/st/f1/stm32f1.dtsi:363 */
			st,adc-internal-regulator = "none";                        /* in zephyr/dts/arm/st/f1/stm32f1.dtsi:364 */
			st,adc-has-injected-support;                               /* in zephyr/dts/arm/st/f1/stm32f1.dtsi:365 */
			pinctrl-0 = < &adc1_in0_pa0 >;                             /* in zephyr/boards/others/stm32_min_dev/stm32_min_dev.dts:127 */
			pinctrl-names = "default";                                 /* in zephyr/boards/others/stm32_min_dev/stm32_min_dev.dts:128 */
			status = "okay";                                           /* in zephyr/boards/others/stm32_min_dev/stm32_min_dev.dts:129 */
			phandle = < 0x21 >;                                        /* in zephyr/dts/arm/st/f1/stm32f1.dtsi:400 */
		};

		/* node '/soc/dma@40020000' defined in zephyr/dts/arm/st/f1/stm32f1.dtsi:369 */
		dma1: dma@40020000 {
			compatible = "st,stm32-dma-v2bis"; /* in zephyr/dts/arm/st/f1/stm32f1.dtsi:370 */
			#dma-cells = < 0x2 >;              /* in zephyr/dts/arm/st/f1/stm32f1.dtsi:371 */
			reg = < 0x40020000 0x400 >;        /* in zephyr/dts/arm/st/f1/stm32f1.dtsi:372 */
			clocks = < &rcc 0x14 0x1 >;        /* in zephyr/dts/arm/st/f1/stm32f1.dtsi:373 */
			interrupts = < 0xb 0x0 >,
			             < 0xc 0x0 >,
			             < 0xd 0x0 >,
			             < 0xe 0x0 >,
			             < 0xf 0x0 >,
			             < 0x10 0x0 >,
			             < 0x11 0x0 >;         /* in zephyr/dts/arm/st/f1/stm32f1.dtsi:374 */
			status = "disabled";               /* in zephyr/dts/arm/st/f1/stm32f1.dtsi:375 */
		};

		/* node '/soc/power@40007000' defined in zephyr/dts/arm/st/f1/stm32f1.dtsi:378 */
		pwr: power@40007000 {
			compatible = "st,stm32-pwr"; /* in zephyr/dts/arm/st/f1/stm32f1.dtsi:379 */
			reg = < 0x40007000 0x400 >;  /* in zephyr/dts/arm/st/f1/stm32f1.dtsi:380 */

			/* node '/soc/power@40007000/wakeup-controller' defined in zephyr/dts/arm/st/f1/stm32f1.dtsi:382 */
			wakeup-controller {
				compatible = "st,stm32f1-pwr-wkupctrl",
				             "st,stm32-pwr-wkupctrl";   /* in zephyr/dts/arm/st/f1/stm32f1.dtsi:383 */
				#address-cells = < 0x1 >;               /* in zephyr/dts/arm/st/f1/stm32f1.dtsi:384 */
				#size-cells = < 0x0 >;                  /* in zephyr/dts/arm/st/f1/stm32f1.dtsi:385 */
				status = "disabled";                    /* in zephyr/dts/arm/st/f1/stm32f1.dtsi:386 */
				st,max-wkup-line-idx = < 0x1 >;         /* in zephyr/dts/arm/st/f1/stm32f1.dtsi:388 */

				/* node '/soc/power@40007000/wakeup-controller/wkup@1' defined in zephyr/dts/arm/st/f1/stm32f1.dtsi:390 */
				wkup@1 {
					reg = < 0x1 >;                   /* in zephyr/dts/arm/st/f1/stm32f1.dtsi:391 */
					wkup-gpios = < &gpioa 0x0 0x0 >; /* in zephyr/dts/arm/st/f1/stm32f1.dtsi:392 */
				};
			};
		};

		/* node '/soc/usb@40005c00' defined in zephyr/dts/arm/st/f1/stm32f103X6.dtsi:24 */
		usb: zephyr_udc0: usb@40005c00 {
			compatible = "st,stm32-usb";               /* in zephyr/dts/arm/st/f1/stm32f103X6.dtsi:25 */
			reg = < 0x40005c00 0x400 >;                /* in zephyr/dts/arm/st/f1/stm32f103X6.dtsi:26 */
			interrupts = < 0x14 0x0 >;                 /* in zephyr/dts/arm/st/f1/stm32f103X6.dtsi:27 */
			interrupt-names = "usb";                   /* in zephyr/dts/arm/st/f1/stm32f103X6.dtsi:28 */
			num-bidir-endpoints = < 0x8 >;             /* in zephyr/dts/arm/st/f1/stm32f103X6.dtsi:29 */
			ram-size = < 0x200 >;                      /* in zephyr/dts/arm/st/f1/stm32f103X6.dtsi:30 */
			maximum-speed = "full-speed";              /* in zephyr/dts/arm/st/f1/stm32f103X6.dtsi:31 */
			clocks = < &rcc 0x1c 0x800000 >;           /* in zephyr/dts/arm/st/f1/stm32f103X6.dtsi:33 */
			phys = < &usb_fs_phy >;                    /* in zephyr/dts/arm/st/f1/stm32f103X6.dtsi:34 */
			pinctrl-0 = < &usb_dm_pa11 &usb_dp_pa12 >; /* in zephyr/boards/others/stm32_min_dev/stm32_min_dev.dts:121 */
			pinctrl-names = "default";                 /* in zephyr/boards/others/stm32_min_dev/stm32_min_dev.dts:122 */
			status = "okay";                           /* in zephyr/boards/others/stm32_min_dev/stm32_min_dev.dts:123 */
		};

		/* node '/soc/can@40006400' defined in zephyr/dts/arm/st/f1/stm32f103X6.dtsi:37 */
		can1: can@40006400 {
			compatible = "st,stm32-bxcan";    /* in zephyr/dts/arm/st/f1/stm32f103X6.dtsi:38 */
			reg = < 0x40006400 0x400 >;       /* in zephyr/dts/arm/st/f1/stm32f103X6.dtsi:39 */
			interrupts = < 0x13 0x0 >,
			             < 0x14 0x0 >,
			             < 0x15 0x0 >,
			             < 0x16 0x0 >;        /* in zephyr/dts/arm/st/f1/stm32f103X6.dtsi:40 */
			interrupt-names = "TX",
			                  "RX0",
			                  "RX1",
			                  "SCE";          /* in zephyr/dts/arm/st/f1/stm32f103X6.dtsi:41 */
			clocks = < &rcc 0x1c 0x2000000 >; /* in zephyr/dts/arm/st/f1/stm32f103X6.dtsi:42 */
			status = "disabled";              /* in zephyr/dts/arm/st/f1/stm32f103X6.dtsi:43 */
		};

		/* node '/soc/spi@40003800' defined in zephyr/dts/arm/st/f1/stm32f103X8.dtsi:26 */
		spi2: spi@40003800 {
			compatible = "st,stm32-spi";                                                                               /* in zephyr/dts/arm/st/f1/stm32f103X8.dtsi:27 */
			#address-cells = < 0x1 >;                                                                                  /* in zephyr/dts/arm/st/f1/stm32f103X8.dtsi:28 */
			#size-cells = < 0x0 >;                                                                                     /* in zephyr/dts/arm/st/f1/stm32f103X8.dtsi:29 */
			reg = < 0x40003800 0x400 >;                                                                                /* in zephyr/dts/arm/st/f1/stm32f103X8.dtsi:30 */
			clocks = < &rcc 0x1c 0x4000 >;                                                                             /* in zephyr/dts/arm/st/f1/stm32f103X8.dtsi:31 */
			interrupts = < 0x24 0x0 >;                                                                                 /* in zephyr/dts/arm/st/f1/stm32f103X8.dtsi:32 */
			st,spi-data-width = "limited-8-16-bit";                                                                    /* in zephyr/dts/arm/st/f1/stm32f103X8.dtsi:33 */
			pinctrl-0 = < &spi2_nss_master_pb12 &spi2_sck_master_pb13 &spi2_miso_master_pb14 &spi2_mosi_master_pb15 >; /* in zephyr/boards/others/stm32_min_dev/stm32_min_dev.dts:104 */
			pinctrl-names = "default";                                                                                 /* in zephyr/boards/others/stm32_min_dev/stm32_min_dev.dts:106 */
			status = "okay";                                                                                           /* in zephyr/boards/others/stm32_min_dev/stm32_min_dev.dts:107 */
		};

		/* node '/soc/serial@40004800' defined in zephyr/dts/arm/st/f1/stm32f103X8.dtsi:37 */
		usart3: serial@40004800 {
			compatible = "st,stm32-usart",
			             "st,stm32-uart";                    /* in zephyr/dts/arm/st/f1/stm32f103X8.dtsi:38 */
			reg = < 0x40004800 0x400 >;                      /* in zephyr/dts/arm/st/f1/stm32f103X8.dtsi:39 */
			clocks = < &rcc 0x1c 0x40000 >;                  /* in zephyr/dts/arm/st/f1/stm32f103X8.dtsi:40 */
			resets = < &rctl 0x212 >;                        /* in zephyr/dts/arm/st/f1/stm32f103X8.dtsi:41 */
			interrupts = < 0x27 0x0 >;                       /* in zephyr/dts/arm/st/f1/stm32f103X8.dtsi:42 */
			pinctrl-0 = < &usart3_tx_pb10 &usart3_rx_pb11 >; /* in zephyr/boards/others/stm32_min_dev/stm32_min_dev.dts:72 */
			current-speed = < 0x1c200 >;                     /* in zephyr/boards/others/stm32_min_dev/stm32_min_dev.dts:73 */
			pinctrl-names = "default";                       /* in zephyr/boards/others/stm32_min_dev/stm32_min_dev.dts:74 */
			status = "okay";                                 /* in zephyr/boards/others/stm32_min_dev/stm32_min_dev.dts:75 */
		};

		/* node '/soc/i2c@40005800' defined in zephyr/dts/arm/st/f1/stm32f103X8.dtsi:46 */
		i2c2: i2c@40005800 {
			compatible = "st,stm32-i2c-v1";                /* in zephyr/dts/arm/st/f1/stm32f103X8.dtsi:47 */
			#address-cells = < 0x1 >;                      /* in zephyr/dts/arm/st/f1/stm32f103X8.dtsi:49 */
			#size-cells = < 0x0 >;                         /* in zephyr/dts/arm/st/f1/stm32f103X8.dtsi:50 */
			reg = < 0x40005800 0x400 >;                    /* in zephyr/dts/arm/st/f1/stm32f103X8.dtsi:51 */
			clocks = < &rcc 0x1c 0x400000 >;               /* in zephyr/dts/arm/st/f1/stm32f103X8.dtsi:52 */
			interrupts = < 0x21 0x0 >,
			             < 0x22 0x0 >;                     /* in zephyr/dts/arm/st/f1/stm32f103X8.dtsi:53 */
			interrupt-names = "event",
			                  "error";                     /* in zephyr/dts/arm/st/f1/stm32f103X8.dtsi:54 */
			pinctrl-0 = < &i2c2_scl_pb10 &i2c2_sda_pb11 >; /* in zephyr/boards/others/stm32_min_dev/stm32_min_dev.dts:88 */
			pinctrl-names = "default";                     /* in zephyr/boards/others/stm32_min_dev/stm32_min_dev.dts:89 */
			scl-gpios = < &gpiob 0xa 0x0 >;                /* in zephyr/boards/others/stm32_min_dev/stm32_min_dev.dts:90 */
			sda-gpios = < &gpiob 0xb 0x0 >;                /* in zephyr/boards/others/stm32_min_dev/stm32_min_dev.dts:91 */
			status = "okay";                               /* in zephyr/boards/others/stm32_min_dev/stm32_min_dev.dts:92 */
			clock-frequency = < 0x61a80 >;                 /* in zephyr/boards/others/stm32_min_dev/stm32_min_dev.dts:93 */
			phandle = < 0x23 >;                            /* in zephyr/dts/arm/st/f1/stm32f103X8.dtsi:92 */
		};

		/* node '/soc/timers@40000800' defined in zephyr/dts/arm/st/f1/stm32f103X8.dtsi:58 */
		timers4: timers@40000800 {
			compatible = "st,stm32-timers"; /* in zephyr/dts/arm/st/f1/stm32f103X8.dtsi:59 */
			reg = < 0x40000800 0x400 >;     /* in zephyr/dts/arm/st/f1/stm32f103X8.dtsi:60 */
			clocks = < &rcc 0x1c 0x4 >,
			         < &rcc 0x8 0xff >;     /* in zephyr/dts/arm/st/f1/stm32f103X8.dtsi:61 */
			resets = < &rctl 0x202 >;       /* in zephyr/dts/arm/st/f1/stm32f103X8.dtsi:63 */
			interrupts = < 0x1e 0x0 >;      /* in zephyr/dts/arm/st/f1/stm32f103X8.dtsi:64 */
			interrupt-names = "global";     /* in zephyr/dts/arm/st/f1/stm32f103X8.dtsi:65 */
			st,prescaler = < 0x0 >;         /* in zephyr/dts/arm/st/f1/stm32f103X8.dtsi:66 */
			status = "disabled";            /* in zephyr/dts/arm/st/f1/stm32f103X8.dtsi:67 */

			/* node '/soc/timers@40000800/pwm' defined in zephyr/dts/arm/st/f1/stm32f103X8.dtsi:69 */
			pwm {
				compatible = "st,stm32-pwm"; /* in zephyr/dts/arm/st/f1/stm32f103X8.dtsi:70 */
				status = "disabled";         /* in zephyr/dts/arm/st/f1/stm32f103X8.dtsi:71 */
				#pwm-cells = < 0x3 >;        /* in zephyr/dts/arm/st/f1/stm32f103X8.dtsi:72 */
			};

			/* node '/soc/timers@40000800/counter' defined in zephyr/dts/arm/st/f1/stm32f103X8.dtsi:75 */
			counter {
				compatible = "st,stm32-counter"; /* in zephyr/dts/arm/st/f1/stm32f103X8.dtsi:76 */
				status = "disabled";             /* in zephyr/dts/arm/st/f1/stm32f103X8.dtsi:77 */
			};

			/* node '/soc/timers@40000800/qdec' defined in zephyr/dts/arm/st/f1/stm32f103X8.dtsi:80 */
			qdec {
				compatible = "st,stm32-qdec";    /* in zephyr/dts/arm/st/f1/stm32f103X8.dtsi:81 */
				st,input-filter-level = < 0x0 >; /* in zephyr/dts/arm/st/f1/stm32f103X8.dtsi:82 */
				status = "disabled";             /* in zephyr/dts/arm/st/f1/stm32f103X8.dtsi:83 */
			};
		};
	};

	/* node '/cpus' defined in zephyr/dts/arm/st/f1/stm32f1.dtsi:28 */
	cpus {
		#address-cells = < 0x1 >; /* in zephyr/dts/arm/st/f1/stm32f1.dtsi:29 */
		#size-cells = < 0x0 >;    /* in zephyr/dts/arm/st/f1/stm32f1.dtsi:30 */

		/* node '/cpus/cpu@0' defined in zephyr/dts/arm/st/f1/stm32f1.dtsi:32 */
		cpu0: cpu@0 {
			device_type = "cpu";                  /* in zephyr/dts/arm/st/f1/stm32f1.dtsi:33 */
			compatible = "arm,cortex-m3";         /* in zephyr/dts/arm/st/f1/stm32f1.dtsi:34 */
			cpu-power-states = < &stop0 &stop1 >; /* in zephyr/dts/arm/st/f1/stm32f1.dtsi:35 */
			reg = < 0x0 >;                        /* in zephyr/dts/arm/st/f1/stm32f1.dtsi:36 */
		};

		/* node '/cpus/power-states' defined in zephyr/dts/arm/st/f1/stm32f1.dtsi:39 */
		power-states {

			/* node '/cpus/power-states/stop0' defined in zephyr/dts/arm/st/f1/stm32f1.dtsi:40 */
			stop0: stop0 {
				compatible = "zephyr,power-state";    /* in zephyr/dts/arm/st/f1/stm32f1.dtsi:41 */
				power-state-name = "suspend-to-idle"; /* in zephyr/dts/arm/st/f1/stm32f1.dtsi:42 */
				substate-id = < 0x0 >;                /* in zephyr/dts/arm/st/f1/stm32f1.dtsi:43 */
				min-residency-us = < 0xf4240 >;       /* in zephyr/dts/arm/st/f1/stm32f1.dtsi:44 */
				exit-latency-us = < 0x190 >;          /* in zephyr/dts/arm/st/f1/stm32f1.dtsi:45 */
				phandle = < 0x1e >;                   /* in zephyr/dts/arm/st/f1/stm32f1.dtsi:35 */
			};

			/* node '/cpus/power-states/stop1' defined in zephyr/dts/arm/st/f1/stm32f1.dtsi:48 */
			stop1: stop1 {
				compatible = "zephyr,power-state";    /* in zephyr/dts/arm/st/f1/stm32f1.dtsi:49 */
				power-state-name = "suspend-to-idle"; /* in zephyr/dts/arm/st/f1/stm32f1.dtsi:50 */
				substate-id = < 0x1 >;                /* in zephyr/dts/arm/st/f1/stm32f1.dtsi:51 */
				min-residency-us = < 0xf4240 >;       /* in zephyr/dts/arm/st/f1/stm32f1.dtsi:52 */
				exit-latency-us = < 0x258 >;          /* in zephyr/dts/arm/st/f1/stm32f1.dtsi:53 */
				phandle = < 0x1f >;                   /* in zephyr/dts/arm/st/f1/stm32f1.dtsi:35 */
			};
		};
	};

	/* node '/memory@20000000' defined in zephyr/dts/arm/st/f1/stm32f1.dtsi:58 */
	sram0: memory@20000000 {
		compatible = "zephyr,memory-region",
		             "mmio-sram";            /* in zephyr/dts/arm/st/f1/stm32f1.dtsi:59 */
		zephyr,memory-region = "SRAM0";      /* in zephyr/dts/arm/st/f1/stm32f1.dtsi:60 */
		reg = < 0x20000000 0x5000 >;         /* in zephyr/dts/arm/st/f1/stm32f103X8.dtsi:11 */
	};

	/* node '/clocks' defined in zephyr/dts/arm/st/f1/stm32f1.dtsi:63 */
	clocks {

		/* node '/clocks/clk-hse' defined in zephyr/dts/arm/st/f1/stm32f1.dtsi:64 */
		clk_hse: clk-hse {
			#clock-cells = < 0x0 >;            /* in zephyr/dts/arm/st/f1/stm32f1.dtsi:65 */
			compatible = "st,stm32-hse-clock"; /* in zephyr/dts/arm/st/f1/stm32f1.dtsi:66 */
			clock-frequency = < 0x7a1200 >;    /* in zephyr/boards/others/stm32_min_dev/stm32_min_dev.dts:38 */
			status = "okay";                   /* in zephyr/boards/others/stm32_min_dev/stm32_min_dev.dts:39 */
			phandle = < 0x20 >;                /* in zephyr/boards/others/stm32_min_dev/stm32_min_dev.dts:44 */
		};

		/* node '/clocks/clk-hsi' defined in zephyr/dts/arm/st/f1/stm32f1.dtsi:70 */
		clk_hsi: clk-hsi {
			#clock-cells = < 0x0 >;         /* in zephyr/dts/arm/st/f1/stm32f1.dtsi:71 */
			compatible = "fixed-clock";     /* in zephyr/dts/arm/st/f1/stm32f1.dtsi:72 */
			clock-frequency = < 0x7a1200 >; /* in zephyr/dts/arm/st/f1/stm32f1.dtsi:73 */
			status = "disabled";            /* in zephyr/dts/arm/st/f1/stm32f1.dtsi:74 */
		};

		/* node '/clocks/clk-lse' defined in zephyr/dts/arm/st/f1/stm32f1.dtsi:77 */
		clk_lse: clk-lse {
			#clock-cells = < 0x0 >;       /* in zephyr/dts/arm/st/f1/stm32f1.dtsi:78 */
			compatible = "fixed-clock";   /* in zephyr/dts/arm/st/f1/stm32f1.dtsi:79 */
			clock-frequency = < 0x8000 >; /* in zephyr/dts/arm/st/f1/stm32f1.dtsi:80 */
			status = "disabled";          /* in zephyr/dts/arm/st/f1/stm32f1.dtsi:81 */
		};

		/* node '/clocks/clk-lsi' defined in zephyr/dts/arm/st/f1/stm32f1.dtsi:84 */
		clk_lsi: clk-lsi {
			#clock-cells = < 0x0 >;       /* in zephyr/dts/arm/st/f1/stm32f1.dtsi:85 */
			compatible = "fixed-clock";   /* in zephyr/dts/arm/st/f1/stm32f1.dtsi:86 */
			clock-frequency = < 0x9c40 >; /* in zephyr/dts/arm/st/f1/stm32f1.dtsi:87 */
			status = "disabled";          /* in zephyr/dts/arm/st/f1/stm32f1.dtsi:88 */
		};

		/* node '/clocks/pll' defined in zephyr/dts/arm/st/f1/stm32f1.dtsi:91 */
		pll: pll {
			#clock-cells = < 0x0 >;              /* in zephyr/dts/arm/st/f1/stm32f1.dtsi:92 */
			compatible = "st,stm32f1-pll-clock"; /* in zephyr/dts/arm/st/f1/stm32f1.dtsi:93 */
			mul = < 0x9 >;                       /* in zephyr/boards/others/stm32_min_dev/stm32_min_dev.dts:43 */
			clocks = < &clk_hse >;               /* in zephyr/boards/others/stm32_min_dev/stm32_min_dev.dts:44 */
			status = "okay";                     /* in zephyr/boards/others/stm32_min_dev/stm32_min_dev.dts:45 */
			phandle = < 0x3 >;                   /* in zephyr/boards/others/stm32_min_dev/stm32_min_dev.dts:49 */
		};
	};

	/* node '/mcos' defined in zephyr/dts/arm/st/f1/stm32f1.dtsi:98 */
	mcos {

		/* node '/mcos/mco1' defined in zephyr/dts/arm/st/f1/stm32f1.dtsi:99 */
		mco1: mco1 {
			compatible = "st,stm32f1-clock-mco"; /* in zephyr/dts/arm/st/f1/stm32f1.dtsi:100 */
			clock-names = "clksel";              /* in zephyr/dts/arm/st/f1/stm32f1.dtsi:101 */
			status = "disabled";                 /* in zephyr/dts/arm/st/f1/stm32f1.dtsi:102 */
		};
	};

	/* node '/dietemp' defined in zephyr/dts/arm/st/f1/stm32f1.dtsi:398 */
	die_temp: dietemp {
		compatible = "st,stm32-temp"; /* in zephyr/dts/arm/st/f1/stm32f1.dtsi:399 */
		io-channels = < &adc1 0x10 >; /* in zephyr/dts/arm/st/f1/stm32f1.dtsi:400 */
		status = "disabled";          /* in zephyr/dts/arm/st/f1/stm32f1.dtsi:401 */
		avgslope = "4.3";             /* in zephyr/dts/arm/st/f1/stm32f1.dtsi:402 */
		v25 = < 0x596 >;              /* in zephyr/dts/arm/st/f1/stm32f1.dtsi:403 */
		ntc;                          /* in zephyr/dts/arm/st/f1/stm32f1.dtsi:404 */
	};

	/* node '/smbus1' defined in zephyr/dts/arm/st/f1/stm32f1.dtsi:407 */
	smbus1: smbus1 {
		compatible = "st,stm32-smbus"; /* in zephyr/dts/arm/st/f1/stm32f1.dtsi:408 */
		#address-cells = < 0x1 >;      /* in zephyr/dts/arm/st/f1/stm32f1.dtsi:409 */
		#size-cells = < 0x0 >;         /* in zephyr/dts/arm/st/f1/stm32f1.dtsi:410 */
		i2c = < &i2c1 >;               /* in zephyr/dts/arm/st/f1/stm32f1.dtsi:411 */
		status = "disabled";           /* in zephyr/dts/arm/st/f1/stm32f1.dtsi:412 */
	};

	/* node '/usbphy' defined in zephyr/dts/arm/st/f1/stm32f103X6.dtsi:47 */
	usb_fs_phy: usbphy {
		compatible = "usb-nop-xceiv"; /* in zephyr/dts/arm/st/f1/stm32f103X6.dtsi:48 */
		#phy-cells = < 0x0 >;         /* in zephyr/dts/arm/st/f1/stm32f103X6.dtsi:49 */
		phandle = < 0x13 >;           /* in zephyr/dts/arm/st/f1/stm32f103X6.dtsi:34 */
	};

	/* node '/smbus2' defined in zephyr/dts/arm/st/f1/stm32f103X8.dtsi:88 */
	smbus2: smbus2 {
		compatible = "st,stm32-smbus"; /* in zephyr/dts/arm/st/f1/stm32f103X8.dtsi:89 */
		#address-cells = < 0x1 >;      /* in zephyr/dts/arm/st/f1/stm32f103X8.dtsi:90 */
		#size-cells = < 0x0 >;         /* in zephyr/dts/arm/st/f1/stm32f103X8.dtsi:91 */
		i2c = < &i2c2 >;               /* in zephyr/dts/arm/st/f1/stm32f103X8.dtsi:92 */
		status = "disabled";           /* in zephyr/dts/arm/st/f1/stm32f103X8.dtsi:93 */
	};

	/* node '/leds' defined in zephyr/boards/others/stm32_min_dev/stm32_min_dev.dts:23 */
	leds {
		compatible = "gpio-leds"; /* in ../Zephyr_Prj/Blink_led/boards/stm32_min_dev_blue.overlay:6 */

		/* node '/leds/led' defined in zephyr/boards/others/stm32_min_dev/stm32_min_dev.dts:26 */
		led: led {
			label = "LD";               /* in zephyr/boards/others/stm32_min_dev/stm32_min_dev.dts:28 */
			gpios = < &gpioc 0xd 0x1 >; /* in zephyr/boards/others/stm32_min_dev/stm32_min_dev_stm32f103x8_blue.overlay:13 */
		};

		/* node '/leds/led_pc13' defined in ../Zephyr_Prj/Blink_led/boards/stm32_min_dev_blue.overlay:8 */
		my_led: led_pc13 {
			gpios = < &gpioc 0xd 0x0 >; /* in ../Zephyr_Prj/Blink_led/boards/stm32_min_dev_blue.overlay:9 */
			label = "user stm32";       /* in ../Zephyr_Prj/Blink_led/boards/stm32_min_dev_blue.overlay:11 */
		};
	};
};
